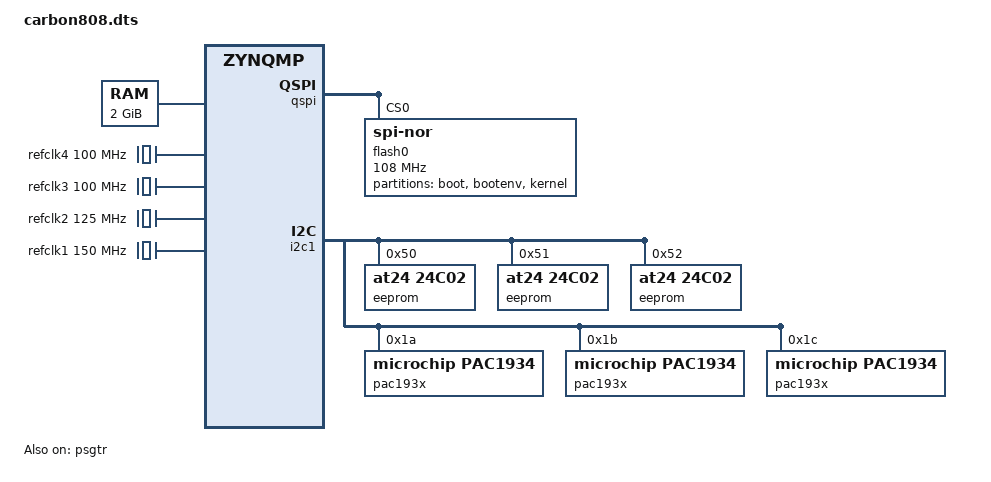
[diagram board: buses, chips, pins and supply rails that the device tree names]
/*
 * CAUTION: This file is automatically generated by Xilinx.
 * Version:
 * Today is: Fri Apr  6 17:23:13 2018
 */


/dts-v1/;
#include "zynqmp.dtsi"
#include "zynqmp-clk-ccf.dtsi"
#include "carbon808-pcw.dtsi"
#include <dt-bindings/interrupt-controller/irq.h>
#include <dt-bindings/pinctrl/pinctrl-zynqmp.h>
#include <dt-bindings/phy/phy.h>
#include <dt-bindings/input/input.h>
#include <dt-bindings/gpio/gpio.h>
/ {
    chosen {
        bootargs = "earlycon clk_ignore_unused root=/dev/mmcblk0p2 rw rootwait";
        stdout-path = "serial0:115200n8";
    };

    aliases {
        serial0 = &uart0;
        serial1 = &uart1;
        spi1 = &spi0;
        spi2 = &spi1;
        spi0 = &qspi;
    };
    memory {
        device_type = "memory";
        reg = <0x0 0x0 0x0 0x7ff00000>;
    };

    clocks: clocks {
            ad9361_clkin: clock@0 {
            #clock-cells = <0>;
            compatible = "adjustable-clock";
            clock-frequency = <40000000>;
            clock-accuracy = <200000>; /* 200 ppm (ppb) */
            clock-output-names = "ad9361_ext_refclk";
            };
    };

    fpga_axi: fpga-axi@0 {
        interrupt-parent = <&gic>;
        compatible = "simple-bus";
        #address-cells = <0x1>;
        #size-cells = <0x1>;
        ranges = <0 0 0 0xffffffff>;

    };
    refclk4: psgtr_dp_clock {
        compatible = "fixed-clock";
        #clock-cells = <0x00>;
        clock-frequency = <100000000>;
    };
 
    refclk3: psgtr_usb_clock {
        compatible = "fixed-clock";
        #clock-cells = <0x00>;
        clock-frequency = <100000000>;
    };
 
    refclk2: psgtr_sata_clock {
        compatible = "fixed-clock";
        #clock-cells = <0x00>;
        clock-frequency = <125000000>; 
    };
 
    refclk1: psgtr_pcie_clock {
        compatible = "fixed-clock";
        #clock-cells = <0x00>;
        clock-frequency = <150000000>;
    };
};
&psgtr {
        status = "okay";
        clocks = <&refclk1>, <&refclk2>, <&refclk3>, <&refclk4>;
        /* ref clk instances used per lane */
        clock-names = "ref0", "ref1", "ref2", "ref3";
};

&qspi {
    #address-cells = <1>;
    #size-cells = <0>;
    flash0: flash@0 {
        compatible = "n25q512a","micron,m25p80";
        spi-tx-bus-width=<1>;
        spi-rx-bus-width=<4>;
        reg = <0x0>;
        #address-cells = <1>;
        #size-cells = <1>;
        spi-max-frequency = <108000000>;
        partition@0x00000000 {
            label = "boot";
            reg = <0x00000000 0x00100000>;
        };
        partition@0x00100000 {
            label = "bootenv";
            reg = <0x00100000 0x00040000>;
        };
        partition@0x00140000 {
            label = "kernel";
            reg = <0x00140000 0x01600000>;
        };
    };
};





/* SDIO */
&sdhci0 {
   status = "disabled";
};
&sdhci1 {
   disable-wp;
   no-1-8-v;
   /* broken-adma2; */
};

&qspi {
    #address-cells = <1>;
    #size-cells = <0>;
    flash0: flash@0 {
         compatible = "jedec,spi-nor";
        reg = <0x0>;
        #address-cells = <1>;
        #size-cells = <1>;
    };
};


/* DMA not used: Reduce error messages on linux.*/

&lpd_dma_chan1 {
    status = "disabled";
};
&lpd_dma_chan2 {
    status = "disabled";
};
&lpd_dma_chan3 {
    status = "disabled";
};
&lpd_dma_chan4 {
    status = "disabled";
};
&lpd_dma_chan5 {
    status = "disabled";
};
&lpd_dma_chan6 {
    status = "disabled";
};
&lpd_dma_chan7 {
    status = "disabled";
};
&lpd_dma_chan8 {
    status = "disabled";
};

//&usb0 {
//	status = "disabled";
//};

&dwc3_0 {
    status = "disabled";
    dr_mode = "peripheral";
    maximum-speed = "super-speed";
    snps,usb3_lpm_capable;
    snps,dis_u3_susphy_quirk;
    snps,dis_u2_susphy_quirk;
    phy-names = "usb3-phy";
    phys = <&psgtr 2 PHY_TYPE_USB3 0 3>;
};

//&dwc3_1 {
//    status = "okay";
//    dr_mode = "peripheral";
//    maximum-speed = "super-speed";
//    snps,usb3_lpm_capable;
//    phy-names = "usb3-phy";
//    phys = <&lane3 4 0 1 100000000>;
//};

&i2c1 {
    eeprom@50 {
      compatible = "at24,24c02";
      reg = <0x50>;
    };
    eeprom@51 {
      compatible = "at24,24c02";
      reg = <0x51>;
    };
    eeprom@52 {
      compatible = "at24,24c02";
      reg = <0x52>;
    };
    pac193x@1A {
        compatible = "microchip,pac1934";
        reg = <0x1A>;
        samp-rate = <64>;
        status = "okay";

        ch1: channel@0 {
            uohms-shunt-res = <22000>; /* shunt resistor is 22 milliohm */
            rail-name = "Battery";
            channel_enabled;
         };

        ch2: channel@1 {
            uohms-shunt-res = <22000>; /* shunt resistor is 22 milliohm */
            rail-name = "External_USB_C_PD";
            channel_enabled;
        };

        ch3: channel@2 {
            uohms-shunt-res = <5000>; /* shunt resistor is 5 milliohm */
            rail-name = "USB_C_DRP_Out";
            channel_enabled;
            };

         ch4: channel@3 {
            uohms-shunt-res = <5000>; /* shunt resistor is 5 milliohm */
            rail-name = "Main_3_3V_Bus";
            channel_enabled;
            };
    };
    pac193x@1B {
        compatible = "microchip,pac1934";
        reg = <0x1B>;
        samp-rate = <64>;
        status = "okay";

        ch5: channel@0 {
            uohms-shunt-res = <5000>; /* shunt resistor is 5 milliohm */
            rail-name = "SOM";
            channel_enabled;
         };

        ch6: channel@1 {
            uohms-shunt-res = <5000>; /* shunt resistor is 5 milliohm */
            rail-name = "AD936x_BoardA";
            channel_enabled;
        };

        ch7: channel@2 {
            uohms-shunt-res = <5000>; /* shunt resistor is 5 milliohm */
            rail-name = "AD936x_BoardB";
            channel_enabled;
        };

        ch8: channel@3 {
            uohms-shunt-res = <5000>; /* shunt resistor is 5 milliohm */
            rail-name = "1_8V_BUS";
            channel_enabled;
        };
    
    };
    pac193x@1C {
        compatible = "microchip,pac1934";
        reg = <0x1C>;
        samp-rate = <64>;
        status = "okay";

        ch9: channel@0 {
            uohms-shunt-res = <5000>; /* shunt resistor is 5 milliohm */
            rail-name = "5V_TO_DOCK";
            channel_enabled;
         };

        ch10: channel@1 {
            uohms-shunt-res = <5000>; /* shunt resistor is 5 milliohm */
            rail-name = "3_3V_TO_DOCK";
            channel_enabled;
        };

        ch11: channel@2 {
            uohms-shunt-res = <5000>; /* shunt resistor is 5 milliohm */
            rail-name = "1_8V_TO_DOCK";
            channel_enabled;
        };
    
    };
};
